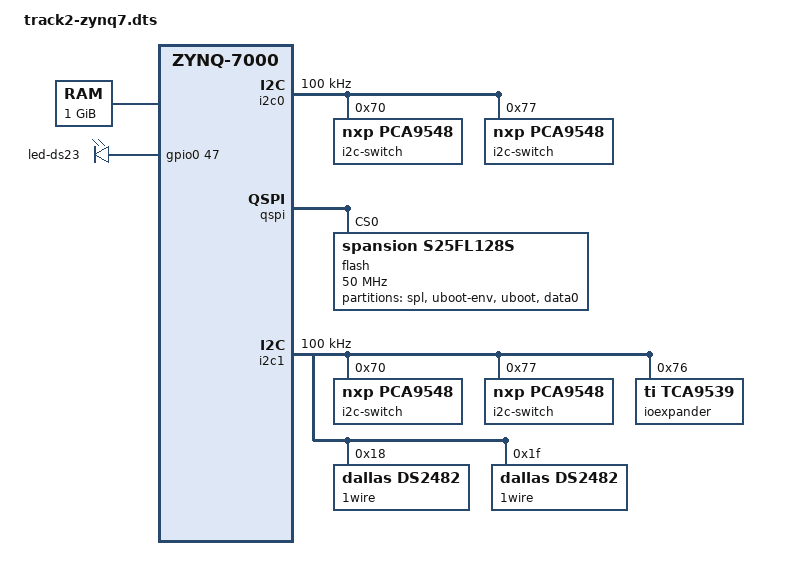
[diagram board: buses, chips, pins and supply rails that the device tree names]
/*
 * CAUTION: This file is automatically generated by Xilinx.
 * Version:
 * Today is: Wed Mar  7 12:10:14 2018
 */


/dts-v1/;
/include/ "zynq-7000.dtsi"
/include/ "pl.dtsi"
/include/ "pcw.dtsi"
/ {
  chosen {
    bootargs = "earlycon ";
    stdout-path = "serial0:115200n8";
  };
  aliases {
    ethernet0 = &gem0;
    serial0 = &uart1;
    serial1 = &uart0;
    serial2 = &axi_uartlite_00;
    serial3 = &axi_uartlite_01;
    serial4 = &axi_uartlite_02;
    serial5 = &axi_uartlite_03;
    serial6 = &axi_uartlite_04;
    serial7 = &axi_uartlite_05;
    serial8 = &axi_uartlite_06;
    serial9 = &axi_uartlite_07;
    serial10 = &axi_uartlite_08;
    serial11 = &axi_uartlite_09;
    serial12 = &axi_uartlite_10;
    serial13 = &axi_uartlite_11;
    spi0 = &qspi;
  };
  memory {
    device_type = "memory";
    reg = <0x0 0x40000000>;
  };
  gpio-leds {
    compatible = "gpio-leds";
    led-d1 {
        label = "led-ds23";
        gpios = <&gpio0 47 0>;
        default-state = "on";
        linux,default-trigger = "heartbeat";
     };
  };
};

&i2c0 {
  clock-frequency = <100000>;
  status = "okay";
   i2c-switch@70 {
    compatible = "nxp,pca9548";
    i2c-mux-idle-disconnect = <1>;
    #address-cells = <1>;
    #size-cells = <0>;
    reg = <0x70>;
    };
   i2c-switch@77 {
    compatible = "nxp,pca9548";
    i2c-mux-idle-disconnect = <1>;
    #address-cells = <1>;
    #size-cells = <0>;
    reg = <0x77>;
    };
};
&qspi {
  is-dual = <0>;
  num-cs = <1>;
  spi-rx-bus-width = <4>;
  spi-tx-bus-width = <4>;
  status = "okay";
  flash@0 {
    compatible = "spansion,s25fl128s", "micron,m25p80", "jedec,spi-nor";
    reg = <0x0>;
    spi-max-frequency = <50000000>;
    #address-cells = <1>;
    #size-cells = <1>;
    partition@qspi-spl {
      label = "spl";
      reg = <0x0 0xE0000>;
    };
    partition@qspi-uboot-env {
      label = "uboot-env";
      reg = <0xE0000 0x20000>;
    };
    partition@qspi-uboot {
      label = "uboot";
      reg = <0x100000 0x200000>;
    };
    partition@qspi-data {
      label = "data0";
      reg = <0x300000 0xD00000>;
    };
  };
};

&i2c1 {
  clock-frequency = <100000>;
  status = "okay";

   i2c-switch@70 {
    compatible = "nxp,pca9548";
    i2c-mux-idle-disconnect = <1>;
    #address-cells = <1>;
    #size-cells = <0>;
    reg = <0x70>;

/include/ "ioexpander.dtsi"

    };

   i2c-switch@77 {
    compatible = "nxp,pca9548";
    i2c-mux-idle-disconnect = <1>;
    #address-cells = <1>;
    #size-cells = <0>;
    reg = <0x77>;

/include/ "ioexpander.dtsi"
    };

    ioexpander@76 {
     compatible = "ti,tca9539";
     reg = <0x76>;
    };

    1wire@18 {
     compatible = "dallas,ds2482";
     reg = <0x18>;
    };

    1wire@1F {
     compatible = "dallas,ds2482";
     reg = <0x1F>;
    };

};

